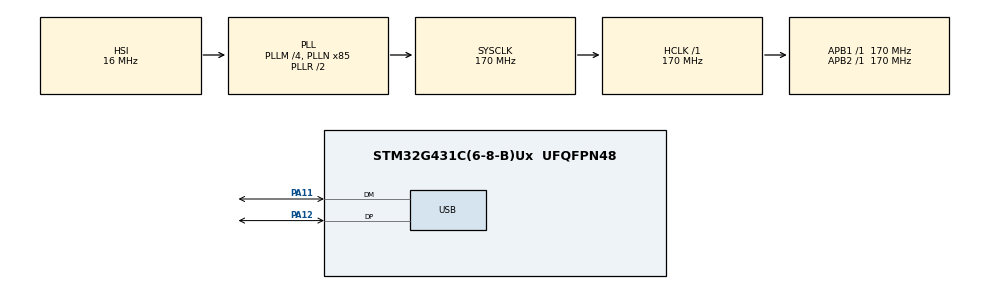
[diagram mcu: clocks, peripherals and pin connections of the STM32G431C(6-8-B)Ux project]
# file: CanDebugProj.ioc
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Mcu.Family=STM32G4
Mcu.Name=STM32G431C(6-8-B)Ux
Mcu.Package=UFQFPN48
NVIC.PriorityGroup=NVIC_PRIORITYGROUP_4
NVIC.USB_LP_IRQn=true\:0\:0\:false\:false\:true\:false\:true\:true
PA11.Mode=Device
PA11.Signal=USB_DM
PA12.Mode=Device
PA12.Signal=USB_DP
PF0-OSC_IN.Mode=HSE-External-Oscillator
PF0-OSC_IN.Signal=RCC_OSC_IN
PF1-OSC_OUT.Mode=HSE-External-Oscillator
PF1-OSC_OUT.Signal=RCC_OSC_OUT
ProjectManager.HeapSize=0x200
ProjectManager.StackSize=0x400
ProjectManager.TargetToolchain=CMake
RCC.ADC12Freq_Value=170000000
RCC.AHBFreq_Value=170000000
RCC.APB1Freq_Value=170000000
RCC.APB1TimFreq_Value=170000000
RCC.APB2Freq_Value=170000000
RCC.APB2TimFreq_Value=170000000
RCC.CK48CLockSelection=RCC_USBCLKSOURCE_HSI48
RCC.CortexFreq_Value=170000000
RCC.EXTERNAL_CLOCK_VALUE=12288000
RCC.HCLKFreq_Value=170000000
RCC.HSE_VALUE=16000000
RCC.HSI48_VALUE=48000000
RCC.HSI_VALUE=16000000
RCC.LSE_VALUE=32768
RCC.PLLM=RCC_PLLM_DIV4
RCC.PLLN=85
RCC.SYSCLKFreq_VALUE=170000000
RCC.SYSCLKSource=RCC_SYSCLKSOURCE_PLLCLK
RCC.USBFreq_Value=48000000
RCC.VCOOutputFreq_Value=340000000
USB_DEVICE.CLASS_NAME_FS=CDC
USB_DEVICE.VirtualMode=Cdc
USB_DEVICE.VirtualModeFS=Cdc_FS
VP_SYS_VS_DBSignals.Mode=DisableDeadBatterySignals
VP_USB_DEVICE_VS_USB_DEVICE_CDC_FS.Mode=CDC_FS
board=custom

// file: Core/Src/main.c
/* USER CODE BEGIN Header */
/**
 ******************************************************************************
 * @file           : main.c
 * @brief          : Main program body
 ******************************************************************************
 * @attention
 *
 * Copyright (c) 2026 STMicroelectronics.
 * All rights reserved.
 *
 * This software is licensed under terms that can be found in the LICENSE file
 * in the root directory of this software component.
 * If no LICENSE file comes with this software, it is provided AS-IS.
 *
 ******************************************************************************
 */
/* USER CODE END Header */
#include "main.h"
#include "usb_device.h"
#include "usbd_cdc_if.h"
#include <math.h>
#include <stdint.h>

/* USER CODE BEGIN PTD */
typedef void (*CommandHandler)(const char *args, char *response,
                               int *response_size);

typedef struct {
  const char *command;
  CommandHandler handler;
} CommandEntry;
/* USER CODE END PTD */

/* USER CODE BEGIN PV */
uint64_t volatile total_cycles = 0;
uint32_t volatile last_cyccnt = 0;
static const float_t VERSION = 0.1f;
/* USER CODE END PV */

/* USER CODE BEGIN PFP */

void SystemClock_Config(void);
static void MX_GPIO_Init(void);

static uint8_t cmd_buf[64];
static uint8_t cmd_idx = 0;

extern volatile uint8_t rx_flag;
extern uint8_t rx_buf[];
extern uint32_t rx_len;

/* USER CODE END PFP */

/* USER CODE BEGIN 0 */

static void cmd_uptime(const char *args, char *response, int *response_size) {
  uint32_t now = DWT->CYCCNT;
  uint64_t cycles = total_cycles + (uint32_t)(now - last_cyccnt);
  uint32_t secounds = (uint32_t)(cycles / 170000000ULL);
  *response_size =
      sprintf(response, "Uptime : %lu:%02lu:%02lu\n", secounds / 3600,
              (secounds % 3600) / 60, secounds % 60);
}

static void cmd_help(const char *args, char *response, int *response_size) {
  //! TODO: feature: from the command_table, generate the help message
  //! automatically

  *response_size =
      sprintf(response, "Available commands:\n- uptime\n- help\n- version\n");
}

static void cmd_version(const char *args, char *response, int *response_size) {
  *response_size = sprintf(response, "Firmware version: %.2f\n", VERSION);
}

static const CommandEntry commands_table[] = {
    {"uptime", cmd_uptime},
    {"help", cmd_help},
    {"version", cmd_version},
};

#define COMMAND_COUNT (sizeof(commands_table) / sizeof(commands_table[0]))

static void dispatch_command(const char *cmd_buf) {
  char response[128];
  int response_size = 0;

  for (int i = 0; i < COMMAND_COUNT; i++) {
    if (strcmp(cmd_buf, commands_table[i].command) == 0) {
      commands_table[i].handler(NULL, response, &response_size);
      if (response_size > 0) {
        CDC_Transmit_FS((uint8_t *)response, response_size);
      }
      return;
    }
  }

  response_size = sprintf(response, "Unknown command: %s\n", cmd_buf);
  CDC_Transmit_FS((uint8_t *)response, response_size);
}

/* USER CODE END 0 */

int main(void) {

  /* MCU Configuration--------------------------------------------------------*/

  /* Reset of all peripherals, Initializes the Flash interface and the Systick.
   */
  HAL_Init();

  /* Configure the system clock */
  SystemClock_Config();

  /* Initialize all configured peripherals */
  MX_GPIO_Init();
  MX_USB_Device_Init();
  /* USER CODE BEGIN 2 */
  __NOP();
  __NOP();

  GPIOC->MODER &= ~GPIO_MODER_MODE4_Msk;
  GPIOC->MODER |= GPIO_MODER_MODE4_0;

  CoreDebug->DEMCR |= CoreDebug_DEMCR_TRCENA_Msk;
  DWT->CYCCNT = 0;
  DWT->CTRL |= DWT_CTRL_CYCCNTENA_Msk;

  // Systick->LOAD = 170000000 - 1; // 1 sec at 170 MHz
  /* USER CODE END 2 */

  /* Infinite loop */
  /* USER CODE BEGIN WHILE */
  while (1) {

    if (rx_flag) {

      rx_flag = 0;
      for (uint32_t i = 0; i < rx_len; i++) {
        uint8_t c = rx_buf[i];

        if (c == '\r' || c == '\n') {
          cmd_buf[cmd_idx] = '\0';
          if (cmd_idx > 0) {
            dispatch_command((char *)cmd_buf);
            cmd_idx = 0;
          }
        } else if (c == 0xAA) {
          // Currently unused, reserved for future binary protocol

          uint8_t command = rx_buf[++i];
          uint8_t data_len = rx_buf[++i];

          switch (command) {

          case 0x1: {
            uint32_t now = DWT->CYCCNT;
            uint64_t cycles = total_cycles + (uint32_t)(now - last_cyccnt);
            uint32_t secounds = (uint32_t)(cycles / 170000000ULL);
            char response[64];
            int len =
                sprintf(response, "Uptime : %lu:%02lu:%02lu\n", secounds / 3600,
                        (secounds % 3600) / 60, secounds % 60);
            CDC_Transmit_FS((uint8_t *)response, len);
            break;
          }
          }
        } else {
          if (cmd_idx < sizeof(cmd_buf) - 1) {
            cmd_buf[cmd_idx++] = c;
          }
        }
      }
    }
    /* USER CODE END WHILE */

  }
}

void SystemClock_Config(void) {
  RCC_OscInitTypeDef RCC_OscInitStruct = {0};
  RCC_ClkInitTypeDef RCC_ClkInitStruct = {0};

  /** Configure the main internal regulator output voltage
   */
  HAL_PWREx_ControlVoltageScaling(PWR_REGULATOR_VOLTAGE_SCALE1_BOOST);

  /** Initializes the RCC Oscillators according to the specified parameters
   * in the RCC_OscInitTypeDef structure.
   */
  RCC_OscInitStruct.OscillatorType =
      RCC_OSCILLATORTYPE_HSI | RCC_OSCILLATORTYPE_HSI48;
  RCC_OscInitStruct.HSIState = RCC_HSI_ON;
  RCC_OscInitStruct.HSICalibrationValue = RCC_HSICALIBRATION_DEFAULT;
  RCC_OscInitStruct.HSI48State = RCC_HSI48_ON;
  RCC_OscInitStruct.PLL.PLLState = RCC_PLL_ON;
  RCC_OscInitStruct.PLL.PLLSource = RCC_PLLSOURCE_HSI;
  RCC_OscInitStruct.PLL.PLLM = RCC_PLLM_DIV4;
  RCC_OscInitStruct.PLL.PLLN = 85;
  RCC_OscInitStruct.PLL.PLLP = RCC_PLLP_DIV2;
  RCC_OscInitStruct.PLL.PLLQ = RCC_PLLQ_DIV2;
  RCC_OscInitStruct.PLL.PLLR = RCC_PLLR_DIV2;
  if (HAL_RCC_OscConfig(&RCC_OscInitStruct) != HAL_OK) {
    Error_Handler();
  }

  /** Initializes the CPU, AHB and APB buses clocks
   */
  RCC_ClkInitStruct.ClockType = RCC_CLOCKTYPE_HCLK | RCC_CLOCKTYPE_SYSCLK |
                                RCC_CLOCKTYPE_PCLK1 | RCC_CLOCKTYPE_PCLK2;
  RCC_ClkInitStruct.SYSCLKSource = RCC_SYSCLKSOURCE_PLLCLK;
  RCC_ClkInitStruct.AHBCLKDivider = RCC_SYSCLK_DIV1;
  RCC_ClkInitStruct.APB1CLKDivider = RCC_HCLK_DIV1;
  RCC_ClkInitStruct.APB2CLKDivider = RCC_HCLK_DIV1;

  if (HAL_RCC_ClockConfig(&RCC_ClkInitStruct, FLASH_LATENCY_4) != HAL_OK) {
    Error_Handler();
  }
}

static void MX_GPIO_Init(void) {

  /* GPIO Ports Clock Enable */
  __HAL_RCC_GPIOF_CLK_ENABLE();
  __HAL_RCC_GPIOA_CLK_ENABLE();

}

void Error_Handler(void) {
  __disable_irq();
  while (1) {
  }
}
#ifdef USE_FULL_ASSERT
/**
 * @brief  Reports the name of the source file and the source line number
 *         where the assert_param error has occurred.
 * @param  file: pointer to the source file name
 * @param  line: assert_param error line source number
 * @retval None
 */
void assert_failed(uint8_t *file, uint32_t line) {
  /* USER CODE BEGIN 6 */
  /* User can add his own implementation to report the file name and line
     number, ex: printf("Wrong parameters value: file %s on line %d\r\n", file,
     line) */
  /* USER CODE END 6 */
}
#endif /* USE_FULL_ASSERT */
